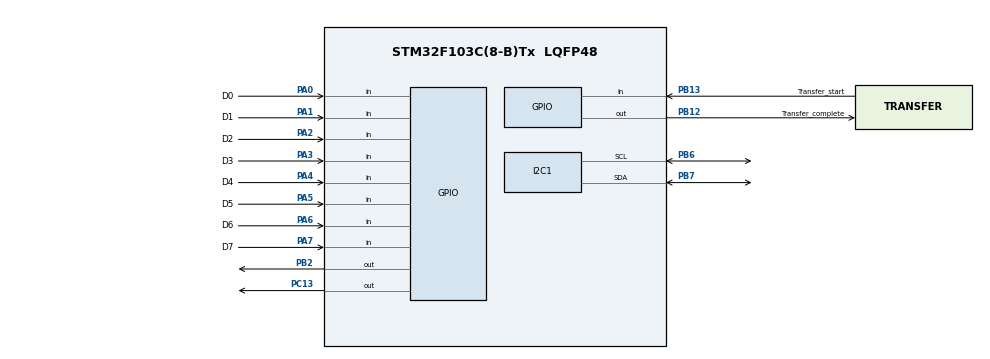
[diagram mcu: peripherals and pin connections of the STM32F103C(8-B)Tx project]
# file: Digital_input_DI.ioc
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I2C1.OwnAddress=0x10
Mcu.Family=STM32F1
Mcu.Name=STM32F103C(8-B)Tx
Mcu.Package=LQFP48
NVIC.I2C1_ER_IRQn=true\:0\:0\:false\:false\:true\:true\:true\:true
NVIC.I2C1_EV_IRQn=true\:0\:0\:false\:false\:true\:true\:true\:true
NVIC.PriorityGroup=NVIC_PRIORITYGROUP_4
PA0-WKUP.GPIO_Label=D0
PA0-WKUP.GPIO_PuPd=GPIO_PULLDOWN
PA0-WKUP.Signal=GPIO_Input
PA1.GPIO_Label=D1
PA1.GPIO_PuPd=GPIO_PULLDOWN
PA1.Signal=GPIO_Input
PA13.Mode=Serial_Wire
PA13.Signal=SYS_JTMS-SWDIO
PA14.Mode=Serial_Wire
PA14.Signal=SYS_JTCK-SWCLK
PA2.GPIO_Label=D2
PA2.GPIO_PuPd=GPIO_PULLDOWN
PA2.Signal=GPIO_Input
PA3.GPIO_Label=D3
PA3.GPIO_PuPd=GPIO_PULLDOWN
PA3.Signal=GPIO_Input
PA4.GPIO_Label=D4
PA4.GPIO_PuPd=GPIO_PULLDOWN
PA4.Signal=GPIO_Input
PA5.GPIO_Label=D5
PA5.GPIO_PuPd=GPIO_PULLDOWN
PA5.Signal=GPIO_Input
PA6.GPIO_Label=D6
PA6.GPIO_PuPd=GPIO_PULLDOWN
PA6.Signal=GPIO_Input
PA7.GPIO_Label=D7
PA7.GPIO_PuPd=GPIO_PULLDOWN
PA7.Signal=GPIO_Input
PB12.GPIO_Label=Transfer_complete
PB12.Signal=GPIO_Output
PB13.GPIO_Label=Transfer_start
PB13.GPIO_PuPd=GPIO_PULLDOWN
PB13.Signal=GPIO_Input
PB2.Signal=GPIO_Output
PB6.Mode=I2C
PB6.Signal=I2C1_SCL
PB7.Mode=I2C
PB7.Signal=I2C1_SDA
PC13-TAMPER-RTC.Signal=GPIO_Output
ProjectManager.HeapSize=0x200
ProjectManager.StackSize=0x400
ProjectManager.TargetToolchain=STM32CubeIDE
RCC.APB1Freq_Value=8000000
RCC.APB2Freq_Value=8000000
board=custom

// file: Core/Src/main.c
/* USER CODE BEGIN Header */
/**
  ******************************************************************************
  * @file           : main.c
  * @brief          : Main program body
  ******************************************************************************
  * @attention
  *
  * Copyright (c) 2025 STMicroelectronics.
  * All rights reserved.
  *
  * This software is licensed under terms that can be found in the LICENSE file
  * in the root directory of this software component.
  * If no LICENSE file comes with this software, it is provided AS-IS.
  *
  ******************************************************************************
  */
/* USER CODE END Header */
#include "main.h"

/* USER CODE BEGIN Includes */
#include "Data_converter.h"
/* USER CODE END Includes */

I2C_HandleTypeDef hi2c1;

/* USER CODE BEGIN PV */

uint8_t dataBuffer;

/* USER CODE END PV */

void SystemClock_Config(void);
static void MX_GPIO_Init(void);
static void MX_I2C1_Init(void);

int main(void)
{

  /* MCU Configuration--------------------------------------------------------*/

  /* Reset of all peripherals, Initializes the Flash interface and the Systick. */
  HAL_Init();

  /* Configure the system clock */
  SystemClock_Config();

  /* Initialize all configured peripherals */
  MX_GPIO_Init();
  MX_I2C1_Init();
  /* USER CODE BEGIN 2 */

  HAL_I2C_Slave_Transmit_IT(&hi2c1, &dataBuffer, 1);
  /* USER CODE END 2 */

  /* Infinite loop */
  /* USER CODE BEGIN WHILE */
  while (1)
  {
	  dataBuffer = getByteData();
    /* USER CODE END WHILE */

  }
}

void SystemClock_Config(void)
{
  RCC_OscInitTypeDef RCC_OscInitStruct = {0};
  RCC_ClkInitTypeDef RCC_ClkInitStruct = {0};

  /** Initializes the RCC Oscillators according to the specified parameters
  * in the RCC_OscInitTypeDef structure.
  */
  RCC_OscInitStruct.OscillatorType = RCC_OSCILLATORTYPE_HSI;
  RCC_OscInitStruct.HSIState = RCC_HSI_ON;
  RCC_OscInitStruct.HSICalibrationValue = RCC_HSICALIBRATION_DEFAULT;
  RCC_OscInitStruct.PLL.PLLState = RCC_PLL_NONE;
  if (HAL_RCC_OscConfig(&RCC_OscInitStruct) != HAL_OK)
  {
    Error_Handler();
  }

  /** Initializes the CPU, AHB and APB buses clocks
  */
  RCC_ClkInitStruct.ClockType = RCC_CLOCKTYPE_HCLK|RCC_CLOCKTYPE_SYSCLK
                              |RCC_CLOCKTYPE_PCLK1|RCC_CLOCKTYPE_PCLK2;
  RCC_ClkInitStruct.SYSCLKSource = RCC_SYSCLKSOURCE_HSI;
  RCC_ClkInitStruct.AHBCLKDivider = RCC_SYSCLK_DIV1;
  RCC_ClkInitStruct.APB1CLKDivider = RCC_HCLK_DIV1;
  RCC_ClkInitStruct.APB2CLKDivider = RCC_HCLK_DIV1;

  if (HAL_RCC_ClockConfig(&RCC_ClkInitStruct, FLASH_LATENCY_0) != HAL_OK)
  {
    Error_Handler();
  }
}

static void MX_I2C1_Init(void)
{

  hi2c1.Instance = I2C1;
  hi2c1.Init.ClockSpeed = 100000;
  hi2c1.Init.DutyCycle = I2C_DUTYCYCLE_2;
  hi2c1.Init.OwnAddress1 = 32;
  hi2c1.Init.AddressingMode = I2C_ADDRESSINGMODE_7BIT;
  hi2c1.Init.DualAddressMode = I2C_DUALADDRESS_DISABLE;
  hi2c1.Init.OwnAddress2 = 0;
  hi2c1.Init.GeneralCallMode = I2C_GENERALCALL_DISABLE;
  hi2c1.Init.NoStretchMode = I2C_NOSTRETCH_DISABLE;
  if (HAL_I2C_Init(&hi2c1) != HAL_OK)
  {
    Error_Handler();
  }

}

static void MX_GPIO_Init(void)
{
  GPIO_InitTypeDef GPIO_InitStruct = {0};

  /* GPIO Ports Clock Enable */
  __HAL_RCC_GPIOC_CLK_ENABLE();
  __HAL_RCC_GPIOA_CLK_ENABLE();
  __HAL_RCC_GPIOB_CLK_ENABLE();

  /*Configure GPIO pin Output Level */
  HAL_GPIO_WritePin(GPIOC, GPIO_PIN_13, GPIO_PIN_RESET);

  /*Configure GPIO pin Output Level */
  HAL_GPIO_WritePin(GPIOB, GPIO_PIN_2|Transfer_complete_Pin, GPIO_PIN_RESET);

  /*Configure GPIO pin : PC13 */
  GPIO_InitStruct.Pin = GPIO_PIN_13;
  GPIO_InitStruct.Mode = GPIO_MODE_OUTPUT_PP;
  GPIO_InitStruct.Pull = GPIO_NOPULL;
  GPIO_InitStruct.Speed = GPIO_SPEED_FREQ_LOW;
  HAL_GPIO_Init(GPIOC, &GPIO_InitStruct);

  /*Configure GPIO pins : D0_Pin D1_Pin D2_Pin D3_Pin
                           D4_Pin D5_Pin D6_Pin D7_Pin */
  GPIO_InitStruct.Pin = D0_Pin|D1_Pin|D2_Pin|D3_Pin
                          |D4_Pin|D5_Pin|D6_Pin|D7_Pin;
  GPIO_InitStruct.Mode = GPIO_MODE_INPUT;
  GPIO_InitStruct.Pull = GPIO_PULLDOWN;
  HAL_GPIO_Init(GPIOA, &GPIO_InitStruct);

  /*Configure GPIO pins : PB2 Transfer_complete_Pin */
  GPIO_InitStruct.Pin = GPIO_PIN_2|Transfer_complete_Pin;
  GPIO_InitStruct.Mode = GPIO_MODE_OUTPUT_PP;
  GPIO_InitStruct.Pull = GPIO_NOPULL;
  GPIO_InitStruct.Speed = GPIO_SPEED_FREQ_LOW;
  HAL_GPIO_Init(GPIOB, &GPIO_InitStruct);

  /*Configure GPIO pin : Transfer_start_Pin */
  GPIO_InitStruct.Pin = Transfer_start_Pin;
  GPIO_InitStruct.Mode = GPIO_MODE_INPUT;
  GPIO_InitStruct.Pull = GPIO_PULLDOWN;
  HAL_GPIO_Init(Transfer_start_GPIO_Port, &GPIO_InitStruct);

}

/* USER CODE BEGIN 4 */
void HAL_I2C_SlaveTxCpltCallback(I2C_HandleTypeDef *hi2c){
	if (hi2c->Instance == I2C1)
	{
		HAL_I2C_Slave_Transmit_IT(&hi2c1, &dataBuffer, 1);
	    //HAL_GPIO_TogglePin(GPIOB, GPIO_PIN_2);
		HAL_GPIO_TogglePin(GPIOC, GPIO_PIN_13);
	}
}

void HAL_I2C_ErrorCallback(I2C_HandleTypeDef *hi2c)
{
    if (hi2c->Instance == I2C1)
    {
    	HAL_I2C_Slave_Transmit_IT(&hi2c1, &dataBuffer, 1);
    }
}
/* USER CODE END 4 */

void Error_Handler(void)
{
  __disable_irq();
  while (1)
  {
  }
}
